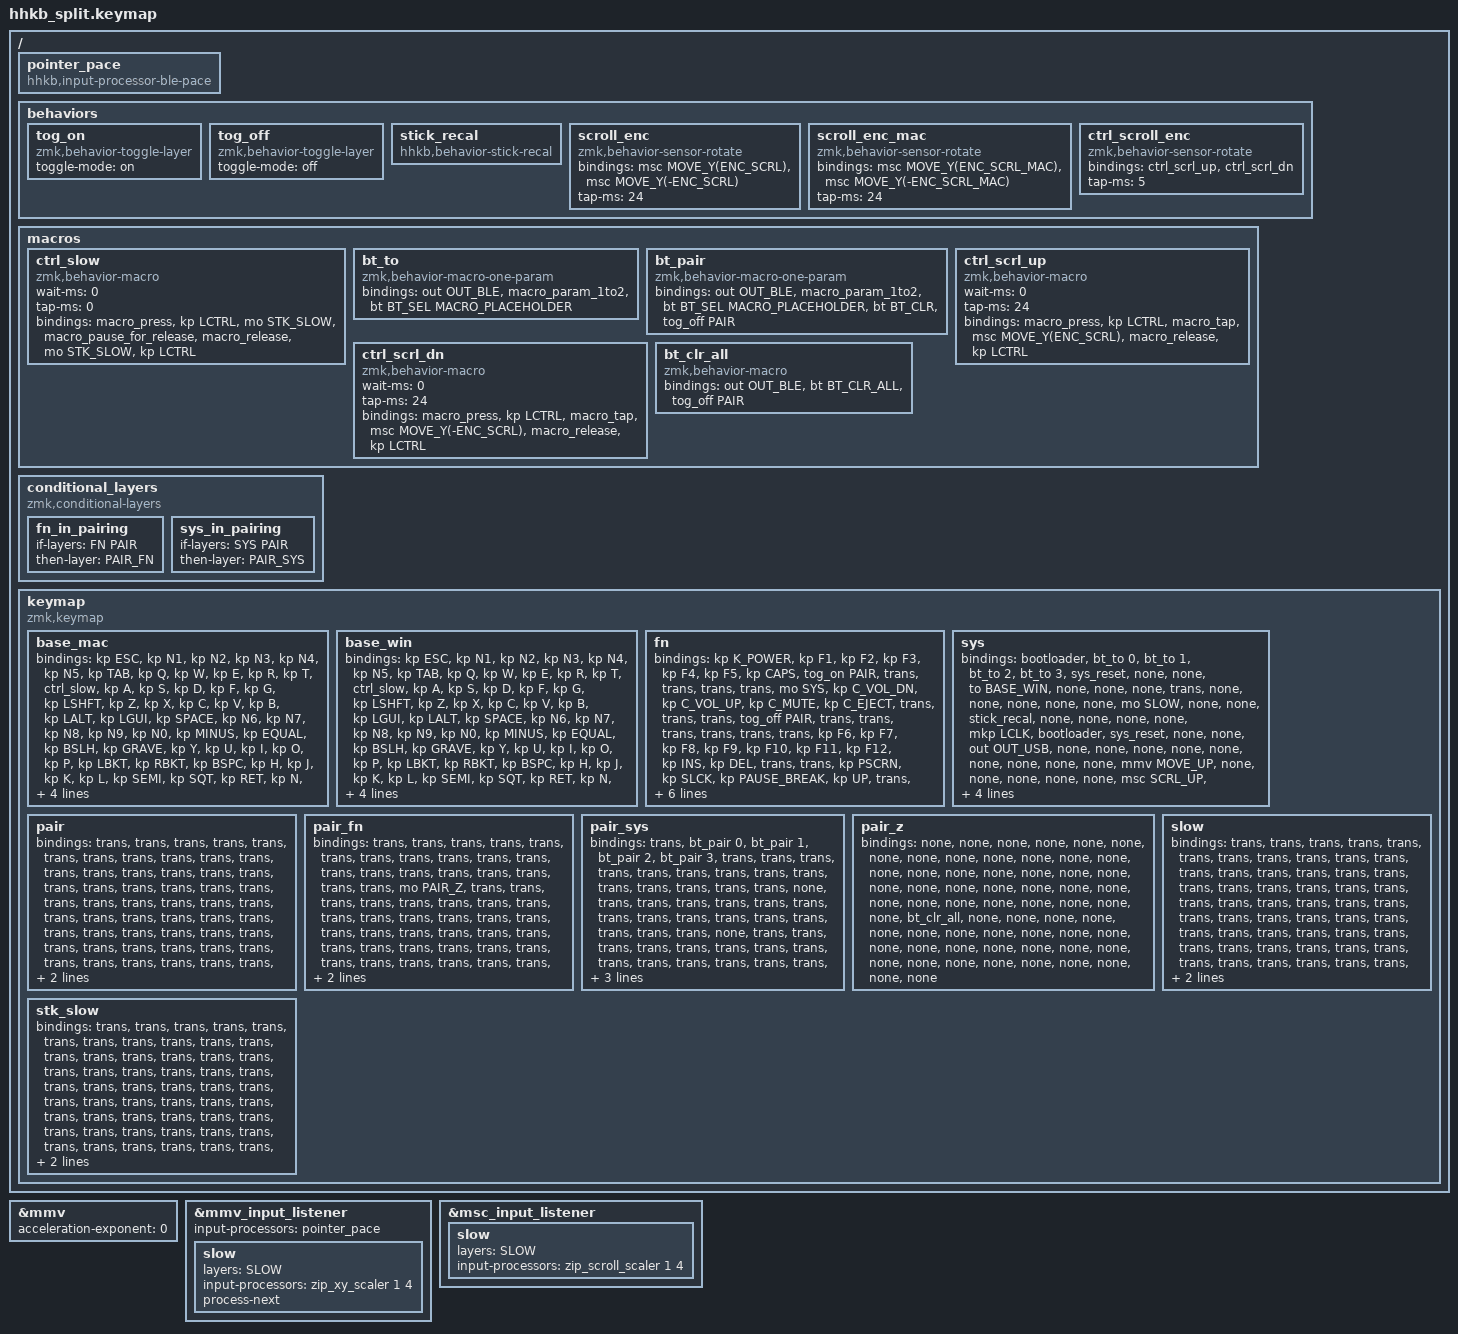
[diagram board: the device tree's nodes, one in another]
/*
 * HHKB Professional HYBRID Type-S のキーマップを分割版へ移植したもの。
 *
 * 出典: docs/hardware/dimensions.md §3（配列）と §4（Fn 面）。
 * Fn 面は Wikimedia Commons の HHKB Pro 2 の KLE 図（刻印つき）から読み取り、
 * 実機写真のキーキャップ前面刻印とも照合した。推測で埋めていない。
 * 2026-09-03: PFU 取扱説明書 P3PC-6641-05EN p.13/15 の Fn 表と全行照合。
 * A/S（音量）だけ KLE の読みが逆で、取説どおり A=Vol Dn・S=Vol Up に直した。
 * Delete は base で BS（実機の DIP SW3 ON 相当）。Del は Fn+` で出す。
 *
 * バインディングの並び順は「左 27 キー → 右 34 キー」で、各半分は
 * 上段左から順に読む。overlay の matrix-transform の map と一対一で対応する。
 *
 *   左 27:  Esc 1 2 3 4 5 / Tab Q W E R T / Ctrl A S D F G /
 *           Shift Z X C V B / Alt Meta L-Space
 *   右 34:  6 7 8 9 0 - = \ ` / Y U I O P [ ] Del /
 *           H J K L ; ' Enter / N M , . / Shift Fn / R-Space Meta Alt
 *
 * レイヤー番号は定義順で決まる。tools/test_invariants.py が固定している。
 *
 * Fn + Ctrl の再現方法:
 *   ZMK の conditional-layers はレイヤー同士の組み合わせしか扱えず、Ctrl は
 *   レイヤーではないので使えない。代わりに FN レイヤー上の Ctrl の位置に
 *   &mo SYS を置く。これで「Fn を押しながら Ctrl」が SYS への入口になり、
 *   Ctrl 単独では通常の Ctrl のまま残る。
 */

#include <behaviors.dtsi>
#include <dt-bindings/zmk/bt.h>
#include <dt-bindings/zmk/keys.h>
#include <dt-bindings/zmk/outputs.h>
/* 最高速（ZMK 既定は 600 / 10 で遅すぎた）。好みで詰める値。 */
#define ZMK_POINTING_DEFAULT_MOVE_VAL 1800
#define ZMK_POINTING_DEFAULT_SCRL_VAL 30
/* エンコーダ 1 刻みぶんの速さ。16ms × ENC_SCRL / 1000 ≧ 1 でなければ何も出ない。 */
#define ENC_SCRL 70
/* Mac の面だけ 1 刻み = 4 段（16ms × 260 / 1000 = 4.16 → 4）。macOS はホイール 1 段を数ピクセルしか動かさず、
 * 実機で「1 刻みで 1/4 行くらい」だった（利用者・2026-10-12）。Windows は 1 段 = 3 行なので、Windows の面は 1 段のまま。 */
#define ENC_SCRL_MAC 260
#include <dt-bindings/zmk/pointing.h>
#include <input/processors.dtsi>

#define BASE_MAC 0
#define BASE_WIN 1
#define FN       2
#define SYS      3
#define PAIR     4  /* ペアリング待機モード（Fn+Q）の印。中身は全部 &trans */
#define PAIR_FN  5  /* FN かつ PAIR のとき（条件レイヤー） */
#define PAIR_SYS 6  /* SYS かつ PAIR のとき（条件レイヤー） */
#define PAIR_Z   7  /* 待機中に Fn+Z を押している間（全削除の入口） */
#define SLOW     8  /* 検討用マウス: Fn+Ctrl+Shift の間だけ 1/4 の速さ */
#define STK_SLOW 9  /* 左 Ctrl を押している間の印。右のスティックだけ 1/8 に（hhkb_pod_remote.overlay が番号 9 で見る） */

/*
 * ペアリング（PFU 取扱説明書 P3PC-6641-05 p.8/15「キー操作」表に合わせた）
 *
 *   Fn+Ctrl+1〜4                … その機器へ切り替え（USB 中なら BLE へ戻る）
 *   Fn+Q → Fn+Ctrl+1〜4         … その番号に登録（既に登録済みなら上書き）
 *   Fn+Q → Fn+Z+`               … 全削除
 *   Fn+Q → Fn+Ctrl+`+1〜4       … 個別削除
 *   Fn+X                        … 待機モードを抜ける
 *   Fn+Ctrl+0                   … USB へ
 *
 * 実機は Delete で消すが、Delete→BS（DIP SW3 ON）の設定では
 * 「Delete のすぐ上の `/~ を使う」と取説 p.15 の注記にある。本機は常にその設定。
 *
 * **実機との違い（ZMK の仕組みから来る）:**
 *   - ZMK の「上書き登録」は「その枠の結合を消して広告し直す」なので、
 *     個別削除と登録は同じ動作になる。消したあとは OFF にならず、
 *     その番号で相手を待つ（青の速い点滅）。**電源スイッチが無いので OFF にしない。**
 *   - 全削除のあとも OFF にならず、1 番で相手を待つ。
 *   - Fn+X は「待機を抜ける」だけ。番号を選んで広告を始めたあとの
 *     取り消しは、Fn+Ctrl+（元の番号）で戻る。
 *   - 全削除はホストとの結合だけを消す。左右間の結合は消えない（ZMK の
 *     zmk_ble_clear_all_bonds はプロファイルの枠だけを回る）。
 */

/ {
	/* ポインタの動きを BLE で 1 個ずつ送る入力プロセッサ（firmware/src/input_ble_pointer_pace.c）。
	 * マウスキー（下の &mmv_input_listener）と、右のスティック（hhkb_pod_remote.overlay）の両方が使う。 */
	pointer_pace: pointer_pace {
		compatible = "hhkb,input-processor-ble-pace";
		#input-processor-cells = <0>;
	};

	behaviors {
		tog_on: tog_on {
			compatible = "zmk,behavior-toggle-layer";
			#binding-cells = <1>;
			toggle-mode = "on";
		};
		tog_off: tog_off {
			compatible = "zmk,behavior-toggle-layer";
			#binding-cells = <1>;
			toggle-mode = "off";
		};
		/* スティックの中心を取り直す（firmware/src/behavior_stick_recal.c）。
		 * **左右共通のキーマップに置く**: 右のポッドに届くには、右の
		 * devicetree にも同じ名前のノードが要る。名前は 15 文字以内。 */
		stick_recal: stick_recal {
			compatible = "hhkb,behavior-stick-recal";
			#binding-cells = <0>;
		};

		/*
		 * 検討用: 左のロータリーエンコーダ（encoder-trial・2026-10-06）
		 *   回す          : マウスホイール
		 *   Fn + 回す     : Ctrl + ホイール（拡大縮小。Ctrl がつまみから遠いため）
		 *   押す          : 中クリック     Fn + 押す : 右クリック
		 *   （2026-10-12 から。左クリックは右のスティックの押し込みへ移した: hhkb_pod_remote.overlay）
		 *
		 * sensor-rotate は「割り当てを押す → tap-ms 待つ → 離す」。&msc は
		 * 押している間 16ms ごとに「速さ × 16 / 1000」を出し、**整数に満たない
		 * 端数は離した瞬間に捨てる**（behavior_input_two_axis.c の
		 * update_work_scheduling）。だから 1 回めの 16ms で 1 以上にならない速さ
		 * では何も出ない: キー用の 30 は 0.48 × 2 回 = 0.96 → 0（最初の版の誤り）。
		 * **ENC_SCRL 70 なら 16ms で 1.12 → 1 段。tap-ms 24 は「1 回めは過ぎ、
		 * 2 回め（32ms）は来ない」長さ。**1 刻み = ホイール 1 段。
		 */
		scroll_enc: scroll_enc {
			compatible = "zmk,behavior-sensor-rotate";
			#sensor-binding-cells = <0>;
			bindings = <&msc MOVE_Y(ENC_SCRL)>, <&msc MOVE_Y(-ENC_SCRL)>;
			tap-ms = <24>;
		};
		/* Mac の面用。違いは量だけ（ENC_SCRL_MAC）。 */
		scroll_enc_mac: scroll_enc_mac {
			compatible = "zmk,behavior-sensor-rotate";
			#sensor-binding-cells = <0>;
			bindings = <&msc MOVE_Y(ENC_SCRL_MAC)>, <&msc MOVE_Y(-ENC_SCRL_MAC)>;
			tap-ms = <24>;
		};
		ctrl_scroll_enc: ctrl_scroll_enc {
			compatible = "zmk,behavior-sensor-rotate";
			#sensor-binding-cells = <0>;
			bindings = <&ctrl_scrl_up>, <&ctrl_scrl_dn>;
			tap-ms = <5>;
		};
	};

	macros {
		/*
		 * 左 Ctrl（2026-10-12・利用者「Ctrl を押しながらの時だけ遅く」）。
		 * ふつうの Ctrl を押したまま、印のレイヤー STK_SLOW も立てる。レイヤーの中身は全部 &trans で、
		 * 効くのはスティックの listener の上書き（1/8）だけ。Ctrl としての働きは変わらない。
		 * Fn を先に押していれば、この位置は FN 面の &mo SYS になる（これまでどおり）。
		 * ⚠️ 低速の間は Ctrl が押されている: クリックは Ctrl+クリック、ホイールは拡大縮小になる。
		 */
		ctrl_slow: ctrl_slow {
			compatible = "zmk,behavior-macro";
			#binding-cells = <0>;
			wait-ms = <0>;
			tap-ms = <0>;
			bindings = <&macro_press &kp LCTRL &mo STK_SLOW>,
			           <&macro_pause_for_release>,
			           <&macro_release &mo STK_SLOW &kp LCTRL>;
		};
		/* 機器の切り替え。実機は USB 接続中でも Fn+Ctrl+1〜4 で BT へ移る。 */
		bt_to: bt_to {
			compatible = "zmk,behavior-macro-one-param";
			#binding-cells = <1>;
			bindings = <&out OUT_BLE>,
			           <&macro_param_1to2>, <&bt BT_SEL MACRO_PLACEHOLDER>;
		};
		/* 登録（上書き）／個別削除。選んだ枠の結合を消し、待機を抜ける。 */
		bt_pair: bt_pair {
			compatible = "zmk,behavior-macro-one-param";
			#binding-cells = <1>;
			bindings = <&out OUT_BLE>,
			           <&macro_param_1to2>, <&bt BT_SEL MACRO_PLACEHOLDER>,
			           <&bt BT_CLR>, <&tog_off PAIR>;
		};
		/* Ctrl を押したままホイール 1 刻み（エンコーダの Fn 面）。 */
		ctrl_scrl_up: ctrl_scrl_up {
			compatible = "zmk,behavior-macro";
			#binding-cells = <0>;
			wait-ms = <0>;
			tap-ms = <24>;
			bindings = <&macro_press &kp LCTRL>, <&macro_tap &msc MOVE_Y(ENC_SCRL)>,
			           <&macro_release &kp LCTRL>;
		};
		ctrl_scrl_dn: ctrl_scrl_dn {
			compatible = "zmk,behavior-macro";
			#binding-cells = <0>;
			wait-ms = <0>;
			tap-ms = <24>;
			bindings = <&macro_press &kp LCTRL>, <&macro_tap &msc MOVE_Y(-ENC_SCRL)>,
			           <&macro_release &kp LCTRL>;
		};
		bt_clr_all: bt_clr_all {
			compatible = "zmk,behavior-macro";
			#binding-cells = <0>;
			bindings = <&out OUT_BLE>, <&bt BT_CLR_ALL>, <&tog_off PAIR>;
		};
	};

	conditional_layers {
		compatible = "zmk,conditional-layers";
		fn_in_pairing {
			if-layers = <FN PAIR>;
			then-layer = <PAIR_FN>;
		};
		sys_in_pairing {
			if-layers = <SYS PAIR>;
			then-layer = <PAIR_SYS>;
		};
	};

	keymap {
		compatible = "zmk,keymap";

		/* ------------------------------------------------------------
		 * 0: Mac モード（起動時の既定）
		 *    ◇ = Command、Alt = Option
		 * ------------------------------------------------------------ */
		base_mac {
			bindings = <
			/* --- 左 27 --- */
			&kp ESC    &kp N1 &kp N2 &kp N3 &kp N4 &kp N5
			&kp TAB    &kp Q  &kp W  &kp E  &kp R  &kp T
			&ctrl_slow &kp A  &kp S  &kp D  &kp F  &kp G
			&kp LSHFT  &kp Z  &kp X  &kp C  &kp V  &kp B
			&kp LALT   &kp LGUI  &kp SPACE
			/* --- 右 34 --- */
			&kp N6 &kp N7 &kp N8 &kp N9 &kp N0    &kp MINUS &kp EQUAL &kp BSLH  &kp GRAVE
			&kp Y  &kp U  &kp I  &kp O  &kp P     &kp LBKT  &kp RBKT  &kp BSPC
			&kp H  &kp J  &kp K  &kp L  &kp SEMI  &kp SQT   &kp RET
			&kp N  &kp M  &kp COMMA &kp DOT &kp SLASH &kp RSHFT &mo FN
			&kp SPACE  &kp RGUI  &kp RALT
			/* --- 左のエンコーダの押し込み（62 個目）: 中クリック（ホイールを押す）--- */
			&mkp MCLK
			/* --- 右のスティックの押し込み（63 個目・K_SPEC §10。キーとして配線したとき）: 左クリック --- */
			&mkp LCLK
			>;
			sensor-bindings = <&scroll_enc_mac>;
		};

		/* ------------------------------------------------------------
		 * 1: Windows モード
		 *    ◇ と Alt を入れ替える。実機の DIP SW4 相当。
		 *    Fn + Ctrl + W で入り、Fn + Ctrl + M で戻る。
		 *    電源を切ると Mac へ戻る（実機と同じ挙動）。
		 * ------------------------------------------------------------ */
		base_win {
			bindings = <
			/* --- 左 27 --- */
			&kp ESC    &kp N1 &kp N2 &kp N3 &kp N4 &kp N5
			&kp TAB    &kp Q  &kp W  &kp E  &kp R  &kp T
			&ctrl_slow &kp A  &kp S  &kp D  &kp F  &kp G
			&kp LSHFT  &kp Z  &kp X  &kp C  &kp V  &kp B
			&kp LGUI   &kp LALT  &kp SPACE
			/* --- 右 34 --- */
			&kp N6 &kp N7 &kp N8 &kp N9 &kp N0    &kp MINUS &kp EQUAL &kp BSLH  &kp GRAVE
			&kp Y  &kp U  &kp I  &kp O  &kp P     &kp LBKT  &kp RBKT  &kp BSPC
			&kp H  &kp J  &kp K  &kp L  &kp SEMI  &kp SQT   &kp RET
			&kp N  &kp M  &kp COMMA &kp DOT &kp SLASH &kp RSHFT &mo FN
			&kp SPACE  &kp RALT  &kp RGUI
			/* --- 左のエンコーダの押し込み（62 個目）: 中クリック（ホイールを押す）--- */
			&mkp MCLK
			/* --- 右のスティックの押し込み（63 個目・K_SPEC §10。キーとして配線したとき）: 左クリック --- */
			&mkp LCLK
			>;
			sensor-bindings = <&scroll_enc>;
		};

		/* ------------------------------------------------------------
		 * 2: Fn（押している間だけ）
		 *    実機の刻印をそのまま移植。&trans は下のレイヤーへ素通し。
		 *    矢印は [ ; ' / の 4 キーで、いずれも右半分にある。
		 * ------------------------------------------------------------ */
		fn {
			bindings = <
			/* --- 左 27 --- */
			&kp K_POWER &kp F1 &kp F2 &kp F3 &kp F4 &kp F5
			&kp CAPS    &tog_on PAIR &trans &trans &trans &trans
			&mo SYS     &kp C_VOL_DN &kp C_VOL_UP &kp C_MUTE &kp C_EJECT &trans
			&trans      &trans &tog_off PAIR &trans &trans &trans
			&trans      &trans &trans
			/* --- 右 34 --- */
			&kp F6 &kp F7 &kp F8 &kp F9 &kp F10 &kp F11 &kp F12 &kp INS &kp DEL
			&trans &trans &kp PSCRN &kp SLCK &kp PAUSE_BREAK &kp UP    &trans &trans
			&kp KP_MULTIPLY &kp KP_DIVIDE &kp HOME &kp PG_UP &kp LEFT  &kp RIGHT &trans
			&kp KP_PLUS &kp KP_MINUS &kp END &kp PG_DN &kp DOWN &trans &trans
			&trans &kp C_STOP &trans
			/* --- 左のエンコーダの押し込み（62 個目）--- */
			&mkp RCLK
			/* --- 右のスティックの押し込み（63 個目・K_SPEC §10）--- */
			&trans
			>;
			sensor-bindings = <&ctrl_scroll_enc>;
		};

		/* ------------------------------------------------------------
		 * 3: SYS（Fn + Ctrl を押している間だけ）
		 *    実機と同じ打ち方で BT と OS モードを切り替える。
		 *      Fn+Ctrl+1〜4 : Bluetooth の機器 1〜4 へ切り替え
		 *                     （Fn+Q の後なら登録。上の「ペアリング」参照）
		 *      Fn+Ctrl+0    : USB 接続へ
		 *      Fn+Ctrl+M    : Mac モード
		 *      Fn+Ctrl+W    : Windows モード
		 *      Fn+Ctrl+Esc  : ブートローダへ入る（左）
		 *      Fn+Ctrl+6    : ブートローダへ入る（右）
		 *      Fn+Ctrl+5    : 再起動（左）  Fn+Ctrl+7 : 再起動（右）
		 *
		 *    **検討用（実機に無い）: マウス（2026-09-27〜・mouse-keys-trial）**
		 *      Fn+Ctrl+[ ; ' / : カーソル 上/左/右/下（Fn の矢印と同じ位置）
		 *      Fn+Ctrl+左Space : 左クリック   Fn+Ctrl+右Space : 右クリック
		 *      Fn+Ctrl+L / .  : ホイール 上/下（Fn の PgUp/PgDn と同じ位置）
		 *      上に加えて Shift : 移動もホイールも 1/4（細かい操作用）
		 *    移動は加速なしで最初から一定の速さ（利用者の指定）。
		 *    Shift を「遅く」にしたのは、普段の移動を 3 キーで済ませるため
		 *    （「速く」にすると大半が 4 キー同時押しになる）。
		 *    ホイールは PgUp/PgDn と別物（少しずつ・カーソルの下に効く・
		 *    文字カーソルを動かさない）なので両方置く。
		 *    手をキーボードから離さずに指せれば視線の往復が消えるか、を試すため。
		 *    SYS の空き（&none）だけを使い、HHKB の Fn 面は 1 つも潰していない。
		 *    CONFIG_ZMK_POINTING（左の .conf）と対。外すときは両方消す。
		 *
		 * **ブートローダに入る手段をキーから用意しておくことが要る。**
		 * XIAO のリセットボタンは組み上げると押せない（上を向いており、
		 * 真上に本体基板が来る）。ファームを更新するたびに分解するのは
		 * 現実的でない。3 キー同時なので誤爆もしない。
		 *
		 * 左右それぞれに置いてあるのは、ZMK の &bootloader が押した側で
		 * 効くのか中央側でしか効かないのかを実機で確かめるため
		 * （docs/hardware/task-c3-ble-split.md の確認項目）。
		 * ------------------------------------------------------------ */
		sys {
			bindings = <
			/* --- 左 27 --- */
			&bootloader &bt_to 0 &bt_to 1 &bt_to 2 &bt_to 3 &sys_reset
			&none  &none  &to BASE_WIN &none &none &none
			&trans &none  &none  &none  &none  &none
			&mo SLOW &none &none &stick_recal &none &none
			&none  &none  &mkp LCLK
			/* --- 右 34 --- */
			&bootloader &sys_reset &none &none &out OUT_USB &none &none &none &none
			&none &none &none &none &none &mmv MOVE_UP &none &none
			&none &none &none &msc SCRL_UP &mmv MOVE_LEFT &mmv MOVE_RIGHT &none
			&none &to BASE_MAC &none &msc SCRL_DOWN &mmv MOVE_DOWN &mo SLOW &trans
			&mkp RCLK &none &none
			/* --- 左のエンコーダの押し込み（62 個目）--- */
			&none
			/* --- 右のスティックの押し込み（63 個目・K_SPEC §10）--- */
			&none
			>;
		};

		/* ------------------------------------------------------------
		 * 4: ペアリング待機モード（Fn+Q で入る）。印だけで中身は素通し。
		 *    打鍵はそのまま使える（実機の待機モードも入力できる）。
		 * ------------------------------------------------------------ */
		pair {
			bindings = <
			/* --- 左 27 --- */
			&trans &trans &trans &trans &trans &trans
			&trans &trans &trans &trans &trans &trans
			&trans &trans &trans &trans &trans &trans
			&trans &trans &trans &trans &trans &trans
			&trans &trans &trans
			/* --- 右 34 --- */
			&trans &trans &trans &trans &trans &trans &trans &trans &trans
			&trans &trans &trans &trans &trans &trans &trans &trans
			&trans &trans &trans &trans &trans &trans &trans
			&trans &trans &trans &trans &trans &trans &trans
			&trans &trans &trans
			/* --- 左のエンコーダの押し込み（62 個目）--- */
			&trans
			/* --- 右のスティックの押し込み（63 個目・K_SPEC §10）--- */
			&trans
			>;
		};

		/* ------------------------------------------------------------
		 * 5: 待機中の Fn。Z を押している間だけ全削除の入口が開く。
		 * ------------------------------------------------------------ */
		pair_fn {
			bindings = <
			/* --- 左 27 --- */
			&trans &trans &trans &trans &trans &trans
			&trans &trans &trans &trans &trans &trans
			&trans &trans &trans &trans &trans &trans
			&trans &mo PAIR_Z &trans &trans &trans &trans
			&trans &trans &trans
			/* --- 右 34 --- */
			&trans &trans &trans &trans &trans &trans &trans &trans &trans
			&trans &trans &trans &trans &trans &trans &trans &trans
			&trans &trans &trans &trans &trans &trans &trans
			&trans &trans &trans &trans &trans &trans &trans
			&trans &trans &trans
			/* --- 左のエンコーダの押し込み（62 個目）--- */
			&trans
			/* --- 右のスティックの押し込み（63 個目・K_SPEC §10）--- */
			&trans
			>;
		};

		/* ------------------------------------------------------------
		 * 6: 待機中の Fn+Ctrl。1〜4 で登録（個別削除も同じ）。
		 *    ` は個別削除の手順（Fn+Ctrl+`+番号）で押されるので何もしない。
		 * ------------------------------------------------------------ */
		pair_sys {
			bindings = <
			/* --- 左 27 --- */
			&trans &bt_pair 0 &bt_pair 1 &bt_pair 2 &bt_pair 3 &trans
			&trans &trans &trans &trans &trans &trans
			&trans &trans &trans &trans &trans &trans
			&trans &none &trans &trans &trans &trans
			&trans &trans &trans
			/* --- 右 34 --- */
			&trans &trans &trans &trans &trans &trans &trans &trans &none
			&trans &trans &trans &trans &trans &trans &trans &trans
			&trans &trans &trans &trans &trans &trans &trans
			&trans &trans &trans &trans &trans &trans &trans
			&trans &trans &trans
			/* --- 左のエンコーダの押し込み（62 個目）--- */
			&trans
			/* --- 右のスティックの押し込み（63 個目・K_SPEC §10）--- */
			&trans
			>;
		};

		/* ------------------------------------------------------------
		 * 7: 待機中の Fn+Z。` で全削除。他のキーは何もしない。
		 * ------------------------------------------------------------ */
		pair_z {
			bindings = <
			/* --- 左 27 --- */
			&none &none &none &none &none &none
			&none &none &none &none &none &none
			&none &none &none &none &none &none
			&none &none &none &none &none &none
			&none &none &none
			/* --- 右 34 --- */
			&none &none &none &none &none &none &none &none &bt_clr_all
			&none &none &none &none &none &none &none &none
			&none &none &none &none &none &none &none
			&none &none &none &none &none &none &none
			&none &none &none
			/* --- 左のエンコーダの押し込み（62 個目）--- */
			&none
			/* --- 右のスティックの押し込み（63 個目・K_SPEC §10）--- */
			&none
			>;
		};

		/* ------------------------------------------------------------
		 * 8: 検討用マウスの低速（Fn+Ctrl+Shift の間だけ）。印だけで中身は
		 *    素通し。縮めるのは末尾の listener の上書き。
		 * ------------------------------------------------------------ */
		slow {
			bindings = <
			/* --- 左 27 --- */
			&trans &trans &trans &trans &trans &trans
			&trans &trans &trans &trans &trans &trans
			&trans &trans &trans &trans &trans &trans
			&trans &trans &trans &trans &trans &trans
			&trans &trans &trans
			/* --- 右 34 --- */
			&trans &trans &trans &trans &trans &trans &trans &trans &trans
			&trans &trans &trans &trans &trans &trans &trans &trans
			&trans &trans &trans &trans &trans &trans &trans
			&trans &trans &trans &trans &trans &trans &trans
			&trans &trans &trans
			/* --- 左のエンコーダの押し込み（62 個目）--- */
			&trans
			/* --- 右のスティックの押し込み（63 個目・K_SPEC §10）--- */
			&trans
			>;
		};

		/* ------------------------------------------------------------
		 * 9: 左 Ctrl を押している間の印（スティックだけ 1/8）。中身は素通し。
		 * ------------------------------------------------------------ */
		stk_slow {
			bindings = <
			/* --- 左 27 --- */
			&trans &trans &trans &trans &trans &trans
			&trans &trans &trans &trans &trans &trans
			&trans &trans &trans &trans &trans &trans
			&trans &trans &trans &trans &trans &trans
			&trans &trans &trans
			/* --- 右 34 --- */
			&trans &trans &trans &trans &trans &trans &trans &trans &trans
			&trans &trans &trans &trans &trans &trans &trans &trans
			&trans &trans &trans &trans &trans &trans &trans
			&trans &trans &trans &trans &trans &trans &trans
			&trans &trans &trans
			/* --- 左のエンコーダの押し込み（62 個目）--- */
			&trans
			/* --- 右のスティックの押し込み（63 個目・K_SPEC §10）--- */
			&trans
			>;
		};
	};
};

/* 検討用マウス: 加速なし（指数 0 で押した瞬間から最高速。ZMK の
 * behavior_input_two_axis.c は accel_exp == 0 なら max_speed を返す）。 */
&mmv {
	acceleration-exponent = <0>;
};

/* SLOW の間だけ 1/4。scaler は余りを持ち越すので小さな値でも 0 に潰れない。 */
&mmv_input_listener {
	/* 動きの送り方（BLE で溜めない・捨てない）。いちばん最後に置く。既定では素通し（CONFIG_HHKB_BLE_POINTER_PACE_ACTIVE） */
	input-processors = <&pointer_pace>;
	slow {
		layers = <SLOW>;
		input-processors = <&zip_xy_scaler 1 4>;
		process-next;   /* 上の pointer_pace まで通す（上書きの中の STOP は process-next が無いと効かない） */
	};
};

&msc_input_listener {
	slow {
		layers = <SLOW>;
		input-processors = <&zip_scroll_scaler 1 4>;
	};
};
